# ESP32S31_RADIO register map
Vendor: Espressif; Series: ESP32-S31; File version: 3.52
Registers are 32-bit, read-write, no defined reset value unless marked. A register's access mark holds for its fields unless they carry their own. Offsets are from the block's base; [hi:lo] are bit positions; {n}, {i} and the like mark numbered series.

## WIFI_MAC_CORE_ENABLE — Shared MAC enable gate recovered from the complete hal_enable_mac and hal_disable_mac leaves. The four individual disable-bit meanings are not independently known.
Base 0x20104C00
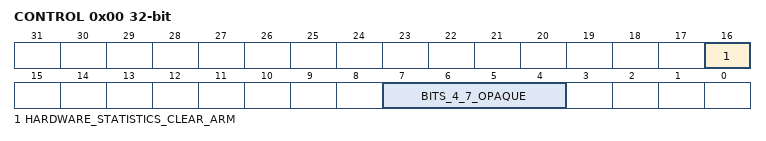
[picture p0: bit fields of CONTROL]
0x00 CONTROL — Project-assigned name. Complete hal_enable_mac clears bits 7:4 in one fresh-read RMW before publishing its interrupt-mask argument; complete hal_disable_mac sets the same four bits. Complete esp_test_clr_hw_statistics independently asserts bit 16 around the separate 0x20104308 bit-zero clear pulse, then clears bit 16.
  [16] HARDWARE_STATISTICS_CLEAR_ARM — Project-assigned name. Set before and cleared after the 0x20104308 clear pulse by complete esp_test_clr_hw_statistics.
  [7:4] BITS_4_7_OPAQUE — Opaque: meaning not established. Zero is the complete hal_enable_mac image and all ones is the complete hal_disable_mac image; individual gate identities remain unknown.
    on write: 0=ENABLED (Clear all four disable gates.); 15=DISABLED (Set all four disable gates.)

## WIFI_MAC_TSF_TIMER — Four-entry TSF timer bank recovered from all complete target, wakeup and enable/disable leaves. Each entry consists of one control word followed by its 32-bit target. The public index is guarded to zero through three by the target and timer-enable leaves; the dedicated wakeup leaves do not contain their own range check.
Base 0x2010D87C
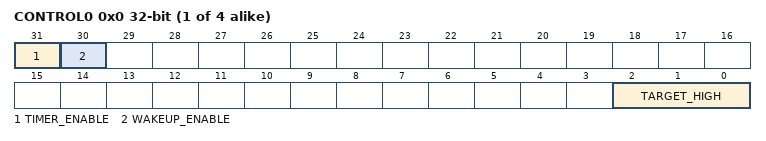
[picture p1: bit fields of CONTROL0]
{0x0+8i} CONTROL{i} (i=0..3) — Project-assigned name. Per-timer control word at 0x2010d87c + index*8. Complete target accessors replace and return the low three bits, bits 34:32 of the 64-bit TSF target. Dedicated leaves set or clear wakeup bit 30, while the timer enable/disable leaves set or clear bit 31.
  [31] TIMER_ENABLE — Project-assigned name. Set by libpp[hal_tsf.o]::hal_enable_tsf_timer and cleared by hal_disable_tsf_timer.
  [30] WAKEUP_ENABLE — Project-assigned name. Set by hal_enable_tsf_timer_wakeup and cleared by hal_disable_tsf_timer_wakeup.
  [2:0] TARGET_HIGH — Project-assigned name. Bits 34:32 of the 64-bit TSF target. Complete libpp[hal_tsf.o]::hal_tsf_timer_set_target replaces them from its third argument and hal_tsf_timer_get_target returns them through its second output pointer; libpp[pm_twt.o]::pm_on_isr_twt_wake passes the high word of the stored 64-bit wake TSF there, and libpp[pm_twt.o]::pm_twt_set_target_tsf parks a timer with an all-ones low word and seven.
{0x4+8i} TARGET{i} (i=0..3) — Project-assigned name. Full 32-bit timer target written by libpp[hal_tsf.o]::hal_tsf_timer_set_target and returned through the first output pointer by hal_tsf_timer_get_target.
  [31:0] VALUE — Project-assigned name.

## COEX_HW_TIMER — Six-entry coexistence timer bank. Complete libcoexist leaves address entry index as 0x2010f400 + index*0x10. The 48-event libcoexist[coexist_core.o]::coex_core_timer_idx_get table of the pinned archive returns timer indices zero through five or 0xff; index five is used only by the PHY grant-protect event 48.
Base 0x2010F400
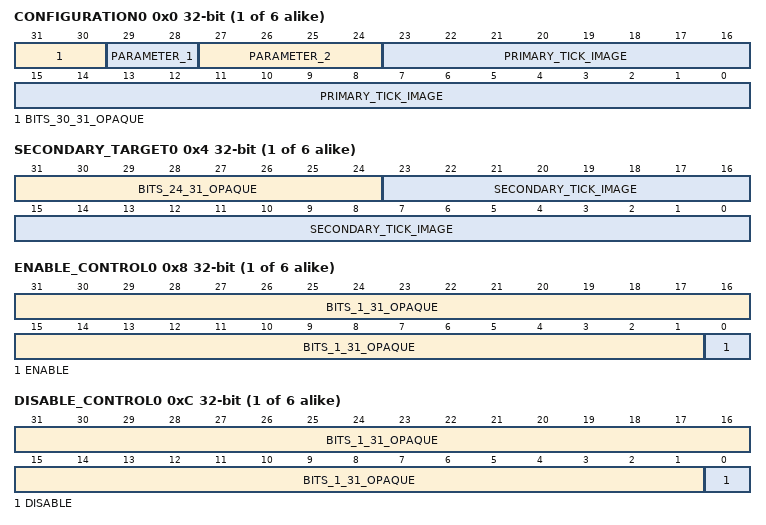
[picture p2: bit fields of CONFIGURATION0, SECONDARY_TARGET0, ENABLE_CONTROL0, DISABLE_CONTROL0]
{0x0+0x10*i} CONFIGURATION{i} (i=0..5) — Project-assigned name. Primary timer word. libcoexist[coexist_hw.o]::coex_hw_timer_set replaces both high nibbles and the low 24-bit tick image through separate fresh-read RMW operations. coex_hw_timer_force clears the low 24 bits; coex_hw_timer_unforce replaces them with 1000.
  [31:30] BITS_30_31_OPAQUE — Opaque: meaning not established. Bits preserved by libcoexist[coexist_hw.o]::coex_hw_timer_set while PARAMETER_1 is replaced.
  [29:28] PARAMETER_1 — Project-assigned name. Low two bits of the second libcoexist[coexist_hw.o]::coex_hw_timer_set argument. Bits 31:30 are preserved by the complete vendor RMW.
  [27:24] PARAMETER_2 — Project-assigned name. Low nibble of the third libcoexist[coexist_hw.o]::coex_hw_timer_set argument.
  [23:0] PRIMARY_TICK_IMAGE — Project-assigned name. Low 24 bits returned by coex_hw_timer_tick_get for the first timer value. The exact counter epoch and units remain part of the reviewed timer conversion rather than the register geometry.
{0x4+0x10*i} SECONDARY_TARGET{i} (i=0..5) — Project-assigned name. Secondary timer word. libcoexist[coexist_hw.o]::coex_hw_timer_set preserves the high byte and replaces the low 24 bits with the converted fourth timer-value argument.
  [31:24] BITS_24_31_OPAQUE — Opaque: meaning not established.
  [23:0] SECONDARY_TICK_IMAGE — Project-assigned name.
{0x8+0x10*i} ENABLE_CONTROL{i} (i=0..5) — Project-assigned name. libcoexist[coexist_hw.o]::coex_hw_timer_enable sets bit zero here after clearing bit zero in the paired disable-control word. libcoexist[coexist_hw.o]::coex_hw_timer_disable performs the inverse transaction.
  [31:1] BITS_1_31_OPAQUE — Opaque: meaning not established.
  [0] ENABLE — Project-assigned name.
{0xC+0x10*i} DISABLE_CONTROL{i} (i=0..5) — Project-assigned name. libcoexist[coexist_hw.o]::coex_hw_timer_disable sets bit zero here after clearing bit zero in the paired enable-control word. libcoexist[coexist_hw.o]::coex_hw_timer_enable performs the inverse transaction.
  [31:1] BITS_1_31_OPAQUE — Opaque: meaning not established.
  [0] DISABLE — Project-assigned name.
